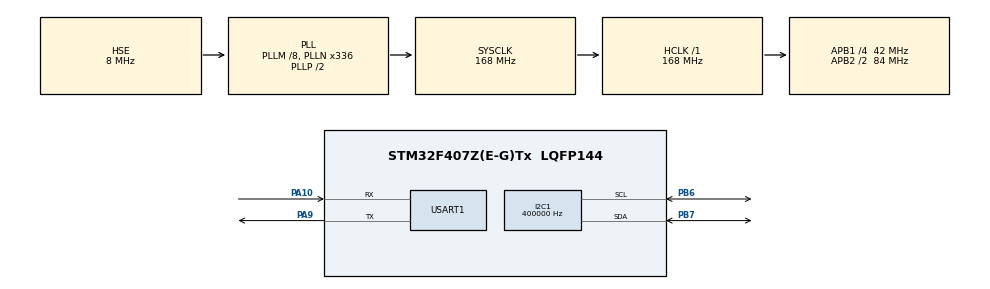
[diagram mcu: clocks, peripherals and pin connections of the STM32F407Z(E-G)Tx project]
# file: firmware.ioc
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FREERTOS.Tasks01=comm,24,1024,StartCommTask,Default,NULL,Dynamic,NULL,NULL;sampling,32,512,StartSamplingTask,Default,NULL,Dynamic,NULL,NULL
FREERTOS.configTOTAL_HEAP_SIZE=16384
I2C1.ClockSpeed=400000
I2C1.I2C_Mode=I2C_Fast
Mcu.Family=STM32F4
Mcu.Name=STM32F407Z(E-G)Tx
Mcu.Package=LQFP144
NVIC.PriorityGroup=NVIC_PRIORITYGROUP_4
NVIC.TIM4_IRQn=true\:15\:0\:false\:false\:true\:false\:false\:true\:true
NVIC.TimeBase=TIM4_IRQn
NVIC.TimeBaseIP=TIM4
NVIC.USART1_IRQn=true\:6\:0\:true\:false\:true\:true\:true\:true\:true
PA10.Mode=Asynchronous
PA10.Signal=USART1_RX
PA13.Mode=Serial_Wire
PA13.Signal=SYS_JTMS-SWDIO
PA14.Mode=Serial_Wire
PA14.Signal=SYS_JTCK-SWCLK
PA9.Mode=Asynchronous
PA9.Signal=USART1_TX
PB6.Mode=I2C
PB6.Signal=I2C1_SCL
PB7.Mode=I2C
PB7.Signal=I2C1_SDA
PH0-OSC_IN.Mode=HSE-External-Oscillator
PH0-OSC_IN.Signal=RCC_OSC_IN
PH1-OSC_OUT.Mode=HSE-External-Oscillator
PH1-OSC_OUT.Signal=RCC_OSC_OUT
ProjectManager.HeapSize=0x200
ProjectManager.StackSize=0x400
ProjectManager.TargetToolchain=CMake
RCC.48MHZClocksFreq_Value=48000000
RCC.AHBFreq_Value=168000000
RCC.APB1CLKDivider=RCC_HCLK_DIV4
RCC.APB1Freq_Value=42000000
RCC.APB1TimFreq_Value=84000000
RCC.APB2CLKDivider=RCC_HCLK_DIV2
RCC.APB2Freq_Value=84000000
RCC.APB2TimFreq_Value=168000000
RCC.CortexFreq_Value=168000000
RCC.HCLKFreq_Value=168000000
RCC.HSE_VALUE=8000000
RCC.HSI_VALUE=16000000
RCC.LSE_VALUE=32768
RCC.PLLM=8
RCC.PLLN=336
RCC.PLLQ=7
RCC.PLLSourceVirtual=RCC_PLLSOURCE_HSE
RCC.SYSCLKFreq_VALUE=168000000
RCC.SYSCLKSource=RCC_SYSCLKSOURCE_PLLCLK
RCC.VCOOutputFreq_Value=336000000
USART1.VirtualMode=VM_ASYNC
VP_FREERTOS_VS_CMSIS_V2.Mode=CMSIS_V2
VP_SYS_VS_tim4.Mode=TIM4
board=custom

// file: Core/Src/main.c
/* USER CODE BEGIN Header */
/**
  ******************************************************************************
  * @file           : main.c
  * @brief          : Main program body
  ******************************************************************************
  * @attention
  *
  * Copyright (c) 2026 STMicroelectronics.
  * All rights reserved.
  *
  * This software is licensed under terms that can be found in the LICENSE file
  * in the root directory of this software component.
  * If no LICENSE file comes with this software, it is provided AS-IS.
  *
  ******************************************************************************
  */
/* USER CODE END Header */
#include "main.h"
#include "cmsis_os.h"
#include "i2c.h"
#include "usart.h"
#include "gpio.h"

void SystemClock_Config(void);
void MX_FREERTOS_Init(void);

int main(void)
{

  /* MCU Configuration--------------------------------------------------------*/

  /* Reset of all peripherals, Initializes the Flash interface and the Systick. */
  HAL_Init();

  /* Configure the system clock */
  SystemClock_Config();

  /* Initialize all configured peripherals */
  MX_GPIO_Init();
  MX_USART1_UART_Init();
  MX_I2C1_Init();

  /* Init scheduler */
  osKernelInitialize();  /* Call init function for freertos objects (in cmsis_os2.c) */
  MX_FREERTOS_Init();

  /* Start scheduler */
  osKernelStart();

  /* We should never get here as control is now taken by the scheduler */

  /* Infinite loop */
  while (1)
  {

  }
}

void SystemClock_Config(void)
{
  RCC_OscInitTypeDef RCC_OscInitStruct = {0};
  RCC_ClkInitTypeDef RCC_ClkInitStruct = {0};

  /** Configure the main internal regulator output voltage
  */
  __HAL_RCC_PWR_CLK_ENABLE();
  __HAL_PWR_VOLTAGESCALING_CONFIG(PWR_REGULATOR_VOLTAGE_SCALE1);

  /** Initializes the RCC Oscillators according to the specified parameters
  * in the RCC_OscInitTypeDef structure.
  */
  RCC_OscInitStruct.OscillatorType = RCC_OSCILLATORTYPE_HSE;
  RCC_OscInitStruct.HSEState = RCC_HSE_ON;
  RCC_OscInitStruct.PLL.PLLState = RCC_PLL_ON;
  RCC_OscInitStruct.PLL.PLLSource = RCC_PLLSOURCE_HSE;
  RCC_OscInitStruct.PLL.PLLM = 8;
  RCC_OscInitStruct.PLL.PLLN = 336;
  RCC_OscInitStruct.PLL.PLLP = RCC_PLLP_DIV2;
  RCC_OscInitStruct.PLL.PLLQ = 7;
  if (HAL_RCC_OscConfig(&RCC_OscInitStruct) != HAL_OK)
  {
    Error_Handler();
  }

  /** Initializes the CPU, AHB and APB buses clocks
  */
  RCC_ClkInitStruct.ClockType = RCC_CLOCKTYPE_HCLK|RCC_CLOCKTYPE_SYSCLK
                              |RCC_CLOCKTYPE_PCLK1|RCC_CLOCKTYPE_PCLK2;
  RCC_ClkInitStruct.SYSCLKSource = RCC_SYSCLKSOURCE_PLLCLK;
  RCC_ClkInitStruct.AHBCLKDivider = RCC_SYSCLK_DIV1;
  RCC_ClkInitStruct.APB1CLKDivider = RCC_HCLK_DIV4;
  RCC_ClkInitStruct.APB2CLKDivider = RCC_HCLK_DIV2;

  if (HAL_RCC_ClockConfig(&RCC_ClkInitStruct, FLASH_LATENCY_5) != HAL_OK)
  {
    Error_Handler();
  }
}

void HAL_TIM_PeriodElapsedCallback(TIM_HandleTypeDef *htim)
{
  if (htim->Instance == TIM4)
  {
    HAL_IncTick();
  }
}

void Error_Handler(void)
{
  __disable_irq();
  while (1)
  {
  }
}

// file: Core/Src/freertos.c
/* USER CODE BEGIN Header */
/**
  ******************************************************************************
  * File Name          : freertos.c
  * Description        : Code for freertos applications
  ******************************************************************************
  * @attention
  *
  * Copyright (c) 2026 STMicroelectronics.
  * All rights reserved.
  *
  * This software is licensed under terms that can be found in the LICENSE file
  * in the root directory of this software component.
  * If no LICENSE file comes with this software, it is provided AS-IS.
  *
  ******************************************************************************
  */
/* USER CODE END Header */

#include "FreeRTOS.h"
#include "task.h"
#include "main.h"
#include "cmsis_os.h"

/* USER CODE BEGIN Includes */
#include "runtime.h"

/* USER CODE END Includes */

/* Definitions for comm */
osThreadId_t commHandle;
const osThreadAttr_t comm_attributes = {
  .name = "comm",
  .stack_size = 1024 * 4,
  .priority = (osPriority_t) osPriorityNormal,
};
/* Definitions for sampling */
osThreadId_t samplingHandle;
const osThreadAttr_t sampling_attributes = {
  .name = "sampling",
  .stack_size = 512 * 4,
  .priority = (osPriority_t) osPriorityAboveNormal,
};

void StartCommTask(void *argument);
void StartSamplingTask(void *argument);

void MX_FREERTOS_Init(void); /* (MISRA C 2004 rule 8.1) */

void MX_FREERTOS_Init(void) {
  /* USER CODE BEGIN Init */
  motion_runtime_init();

  /* USER CODE END Init */

  /* Create the thread(s) */
  /* creation of comm */
  commHandle = osThreadNew(StartCommTask, NULL, &comm_attributes);

  /* creation of sampling */
  samplingHandle = osThreadNew(StartSamplingTask, NULL, &sampling_attributes);

  /* USER CODE BEGIN RTOS_THREADS */
  if (!commHandle || !samplingHandle) Error_Handler();
  /* USER CODE END RTOS_THREADS */

}

void StartCommTask(void *argument)
{
  /* USER CODE BEGIN StartCommTask */
  (void)argument;
  motion_start_console();
  Error_Handler();
  /* USER CODE END StartCommTask */
}

void StartSamplingTask(void *argument)
{
  /* USER CODE BEGIN StartSamplingTask */
  (void)argument;
  motion_start_sampling();
  Error_Handler();
  /* USER CODE END StartSamplingTask */
}
